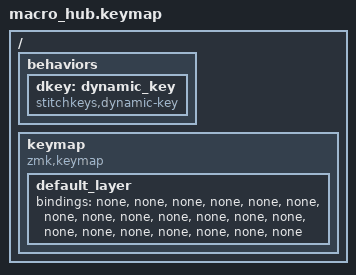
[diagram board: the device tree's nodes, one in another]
#include <behaviors.dtsi>
#include <dt-bindings/zmk/keys.h>
/ {
    behaviors {
        dkey: dynamic_key {
            compatible = "stitchkeys,dynamic-key";
            #binding-cells = <1>;
        };
    };
};
/ {
    keymap {
        compatible = "zmk,keymap";
        default_layer {
            bindings = <
                &none
                &none
                &none
                &none
                &none
                &none
                &none
                &none
                &none
                &none
                &none
                &none
                &none
                &none
                &none
                &none
                &none
                &none
                &none
                &none
            >;
        };
    };
};
